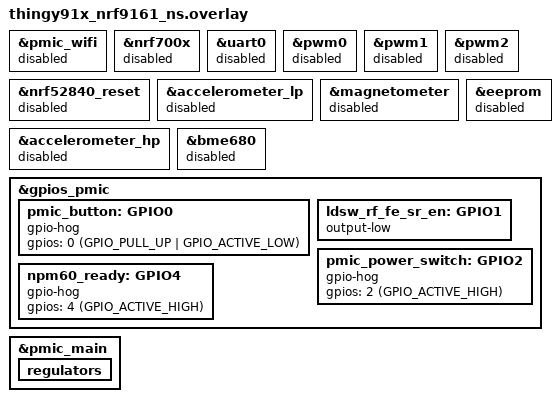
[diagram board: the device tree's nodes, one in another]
// To get started, press Ctrl+Space to bring up the completion menu and view the available nodes.

// You can also use the buttons in the sidebar to perform actions on nodes.
// Actions currently available include:

// * Enabling / disabling the node
// * Adding the bus to a bus
// * Removing the node
// * Connecting ADC channels

// For more help, browse the DeviceTree documentation at https://docs.zephyrproject.org/latest/guides/dts/index.html
// You can also visit the nRF DeviceTree extension documentation at https://nrfconnect.github.io/vscode-nrf-connect/devicetree/nrfdevicetree.html

&pmic_wifi {
        status = "disabled";
};

&nrf700x {
        status = "disabled";
};

&uart0 {
        status = "disabled";
};

&pwm0 {
        status = "disabled";
};

&pwm1 {
        status = "disabled";
};

&pwm2 {
        status = "disabled";
};

&nrf52840_reset {
        status = "disabled";
};

&accelerometer_lp {
        status = "disabled";
};

&magnetometer {
        status = "disabled";
};

&accelerometer_hp {
        status = "disabled";
};

&bme680 {
        status = "disabled";
};

&eeprom {
        status = "disabled";
};

&gpios_pmic {
        pmic_button: GPIO0 {
                gpio-hog;
                gpios = <0 (GPIO_PULL_UP | GPIO_ACTIVE_LOW)>;
        };
        ldsw_rf_fe_sr_en: GPIO1 {
                /delete-property/ output-high;
                output-low;
        };
        pmic_power_switch: GPIO2 {
                gpio-hog;
                gpios = <2 (GPIO_ACTIVE_HIGH)>;
        };
        /* GPIO3 is an output pin used for the interrupt */
        npm60_ready: GPIO4 {
                gpio-hog;
                gpios = <4 (GPIO_ACTIVE_HIGH)>;
        };
};

&pmic_main {
        regulators {
                /delete-node/ LDO1;
        };
};
